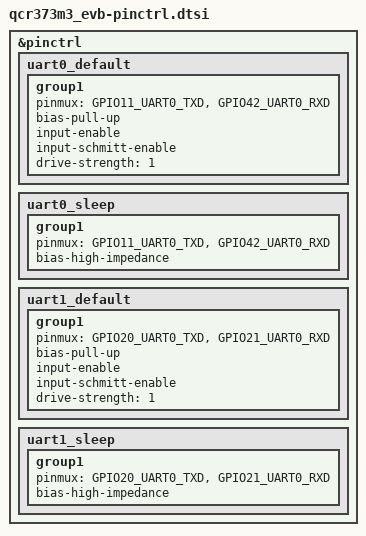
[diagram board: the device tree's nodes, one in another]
/*
 * Copyright (c) Qualcomm Technologies, Inc. and/or its subsidiaries
 * SPDX-License-Identifier: BSD-3-Clause
 */

&pinctrl {
	uart0_default: uart0_default {
		group1 {
			pinmux = <GPIO11_UART0_TXD>,
				 <GPIO42_UART0_RXD>;
			bias-pull-up;
			input-enable;
			input-schmitt-enable;
			drive-strength = <1>;
		};
	};

	uart0_sleep: uart0_sleep {
		group1 {
			pinmux = <GPIO11_UART0_TXD>,
				 <GPIO42_UART0_RXD>;
			bias-high-impedance;
		};
	};

	uart1_default: uart1_default {
		group1 {
			pinmux = <GPIO20_UART0_TXD>,
				 <GPIO21_UART0_RXD>;
			bias-pull-up;
			input-enable;
			input-schmitt-enable;
			drive-strength = <1>;
		};
	};

	uart1_sleep: uart1_sleep {
		group1 {
			pinmux = <GPIO20_UART0_TXD>,
				 <GPIO21_UART0_RXD>;
			bias-high-impedance;
		};
	};
};
